VERSION "Vehicle_Complete_DBC_V1.0_20260722"

NS_ :

	SG_MUL_VAL_;

BS_:

BU_: ECU TCM BCM ABS IC GW ADAS

BA_DEF_  "BusType" STRING ;
BA_DEF_DEF_ "BusType" "CAN";
BA_DEF_ BO_  "GenMsgCycleTime" INT 0 65535;
BA_DEF_DEF_ "GenMsgCycleTime" 100;

;=====================================
; Classical CAN Messages (Standard ID)
;=====================================

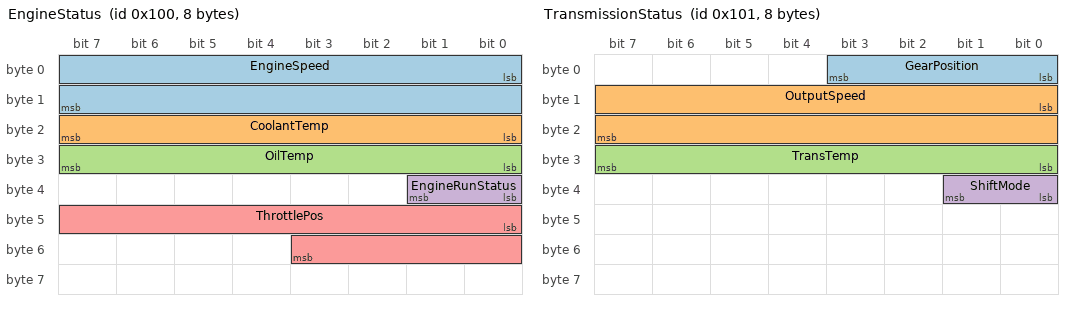
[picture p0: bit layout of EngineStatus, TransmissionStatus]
BO_ 256 EngineStatus: 8 BCM
 BA_ "GenMsgCycleTime" BO_ 256 100  BA_ "GenMsgIsCANFD" BO_ 256 0
 SG_ EngineSpeed		: 0|16@1+ (0.25,0) [0|8000] "rpm" ECU IC TCM
 SG_ CoolantTemp		: 16|8@1+ (1,-40) [-40|215] "degC" ECU IC
 SG_ OilTemp		: 24|8@1+ (1,-40) [-40|215] "degC" ECU
 SG_ EngineRunStatus		: 32|2@1+ (1,0) [0|3] "None" ECU IC BCM
 SG_ ThrottlePos		: 40|12@1+ (0.025,0) [0|100] "%" ECU TCM
BO_ 257 TransmissionStatus: 8 TCM
 BA_ "GenMsgCycleTime" BO_ 257 50  BA_ "GenMsgIsCANFD" BO_ 257 0
 SG_ GearPosition		: 0|4@1+ (1,0) [0|15] "None" ECU IC BCM
 SG_ OutputSpeed		: 8|16@1+ (0.125,0) [0|8000] "rpm" ECU IC TCM
 SG_ TransTemp		: 24|8@1+ (1,-40) [-40|215] "degC" TCM ECU
 SG_ ShiftMode		: 32|2@1+ (1,0) [0|3] "None" IC BCM
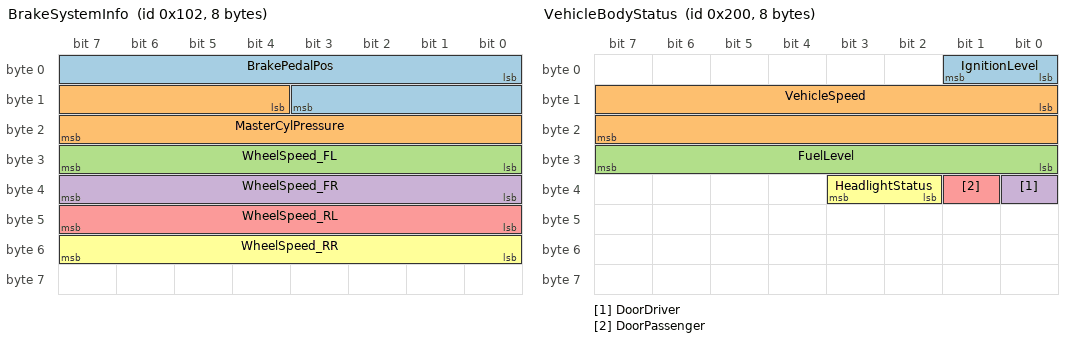
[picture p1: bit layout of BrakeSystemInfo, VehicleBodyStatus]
BO_ 258 BrakeSystemInfo: 8 ABS
 BA_ "GenMsgCycleTime" BO_ 258 20  BA_ "GenMsgIsCANFD" BO_ 258 0
 SG_ BrakePedalPos		: 0|12@1+ (0.025,0) [0|100] "%" ECU ABS IC
 SG_ MasterCylPressure		: 12|12@1+ (0.5,0) [0|200] "bar" ABS ECU
 SG_ WheelSpeed_FL		: 24|8@1+ (0.1,0) [0|250] "km/h" ABS IC
 SG_ WheelSpeed_FR		: 32|8@1+ (0.1,0) [0|250] "km/h" ABS IC
 SG_ WheelSpeed_RL		: 40|8@1+ (0.1,0) [0|250] "km/h" ABS IC
 SG_ WheelSpeed_RR		: 48|8@1+ (0.1,0) [0|250] "km/h" ABS IC
BO_ 512 VehicleBodyStatus: 8 BCM
 BA_ "GenMsgCycleTime" BO_ 512 100  BA_ "GenMsgIsCANFD" BO_ 512 0
 SG_ IgnitionLevel		: 0|2@1+ (1,0) [0|3] "None" ECU IC GW
 SG_ VehicleSpeed		: 8|16@1+ (0.01,0) [0|250] "km/h" ABS IC ECU
 SG_ FuelLevel		: 24|8@1+ (0.4,0) [0|100] "%" IC BCM
 SG_ DoorDriver		: 32|1@1+ (1,0) [0|1] "None" BCM IC
 SG_ DoorPassenger		: 33|1@1+ (1,0) [0|1] "None" BCM IC
 SG_ HeadlightStatus		: 34|2@1+ (1,0) [0|3] "None" BCM IC
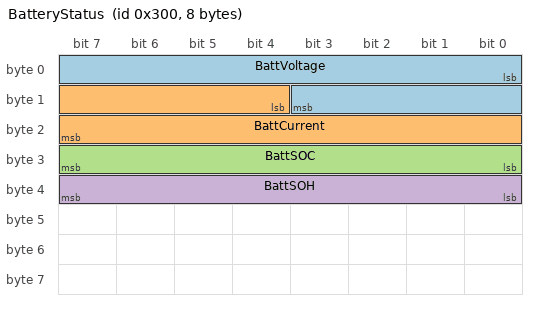
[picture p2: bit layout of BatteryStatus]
BO_ 768 BatteryStatus: 8 ECU
 BA_ "GenMsgCycleTime" BO_ 768 1000  BA_ "GenMsgIsCANFD" BO_ 768 0
 SG_ BattVoltage		: 0|12@1+ (0.01,0) [6|16] "V" BCM IC GW
 SG_ BattCurrent		: 12|12@1+ (0.1,-200) [-200|200] "A" BCM
 SG_ BattSOC		: 24|8@1+ (0.5,0) [0|100] "%" BCM IC
 SG_ BattSOH		: 32|8@1+ (0.5,0) [0|100] "%" ECU BCM

;=====================================
; CAN FD Messages (Extended Payload)
;=====================================

BO_ 1024 ADAS_DrivingData: 64 ADAS
 BA_ "GenMsgCycleTime" BO_ 1024 20  BA_ "GenMsgIsCANFD" BO_ 1024 1
 SG_ ACC_Active		: 0|1@0+ (1,0) [0|1] "None" ADAS ECU IC
 SG_ ACC_SetSpeed		: 1|8@0+ (1,0) [30|180] "km/h" ADAS IC
 SG_ DistanceToLead		: 16|12@0+ (0.1,0) [0|200] "m" ADAS ECU
 SG_ LDW_Status		: 28|2@0+ (1,0) [0|3] "None" ADAS IC BCM
 SG_ FCW_Level		: 32|3@0+ (1,0) [0|5] "None" ADAS ECU IC
 SG_ SteeringAngle		: 48|16@0+ (0.1,-1000) [-1000|1000] "deg" ADAS ABS IC
 SG_ YawRate		: 64|12@0+ (0.01,-50) [-50|50] "deg/s" ADAS ABS ECU
BO_ 1025 Powertrain_Diag: 32 ECU
 BA_ "GenMsgCycleTime" BO_ 1025 500  BA_ "GenMsgIsCANFD" BO_ 1025 1
 SG_ MIL_Lamp		: 0|1@0+ (1,0) [0|1] "None" IC BCM
 SG_ EPC_Lamp		: 1|1@0+ (1,0) [0|1] "None" IC BCM
 SG_ DTC_Count_Engine		: 8|8@0+ (1,0) [0|255] "None" GW
 SG_ DTC_Count_Trans		: 16|8@0+ (1,0) [0|255] "None" GW
 SG_ DTC_Count_Chassis		: 24|8@0+ (1,0) [0|255] "None" GW
 SG_ RuntimeTotal		: 32|32@0+ (1,3600) [0|4294967295] "s" ECU GW
BO_ 1026 EnvironmentalData: 64 GW
 BA_ "GenMsgCycleTime" BO_ 1026 100  BA_ "GenMsgIsCANFD" BO_ 1026 1
 SG_ AmbientTemp		: 0|8@0+ (0.5,-40) [-40|87.5] "degC" BCM IC
 SG_ BarometricPress		: 8|12@0+ (0.1,800) [800|1200] "hPa" ECU ADAS
 SG_ Humidity		: 20|8@0+ (0.4,0) [0|100] "%" ADAS BCM
 SG_ RainSensorLevel		: 32|8@0+ (1,0) [0|15] "None" BCM ADAS
 SG_ LightSensorLevel		: 40|12@0+ (1,0) [0|4095] "lux" BCM IC ADAS
